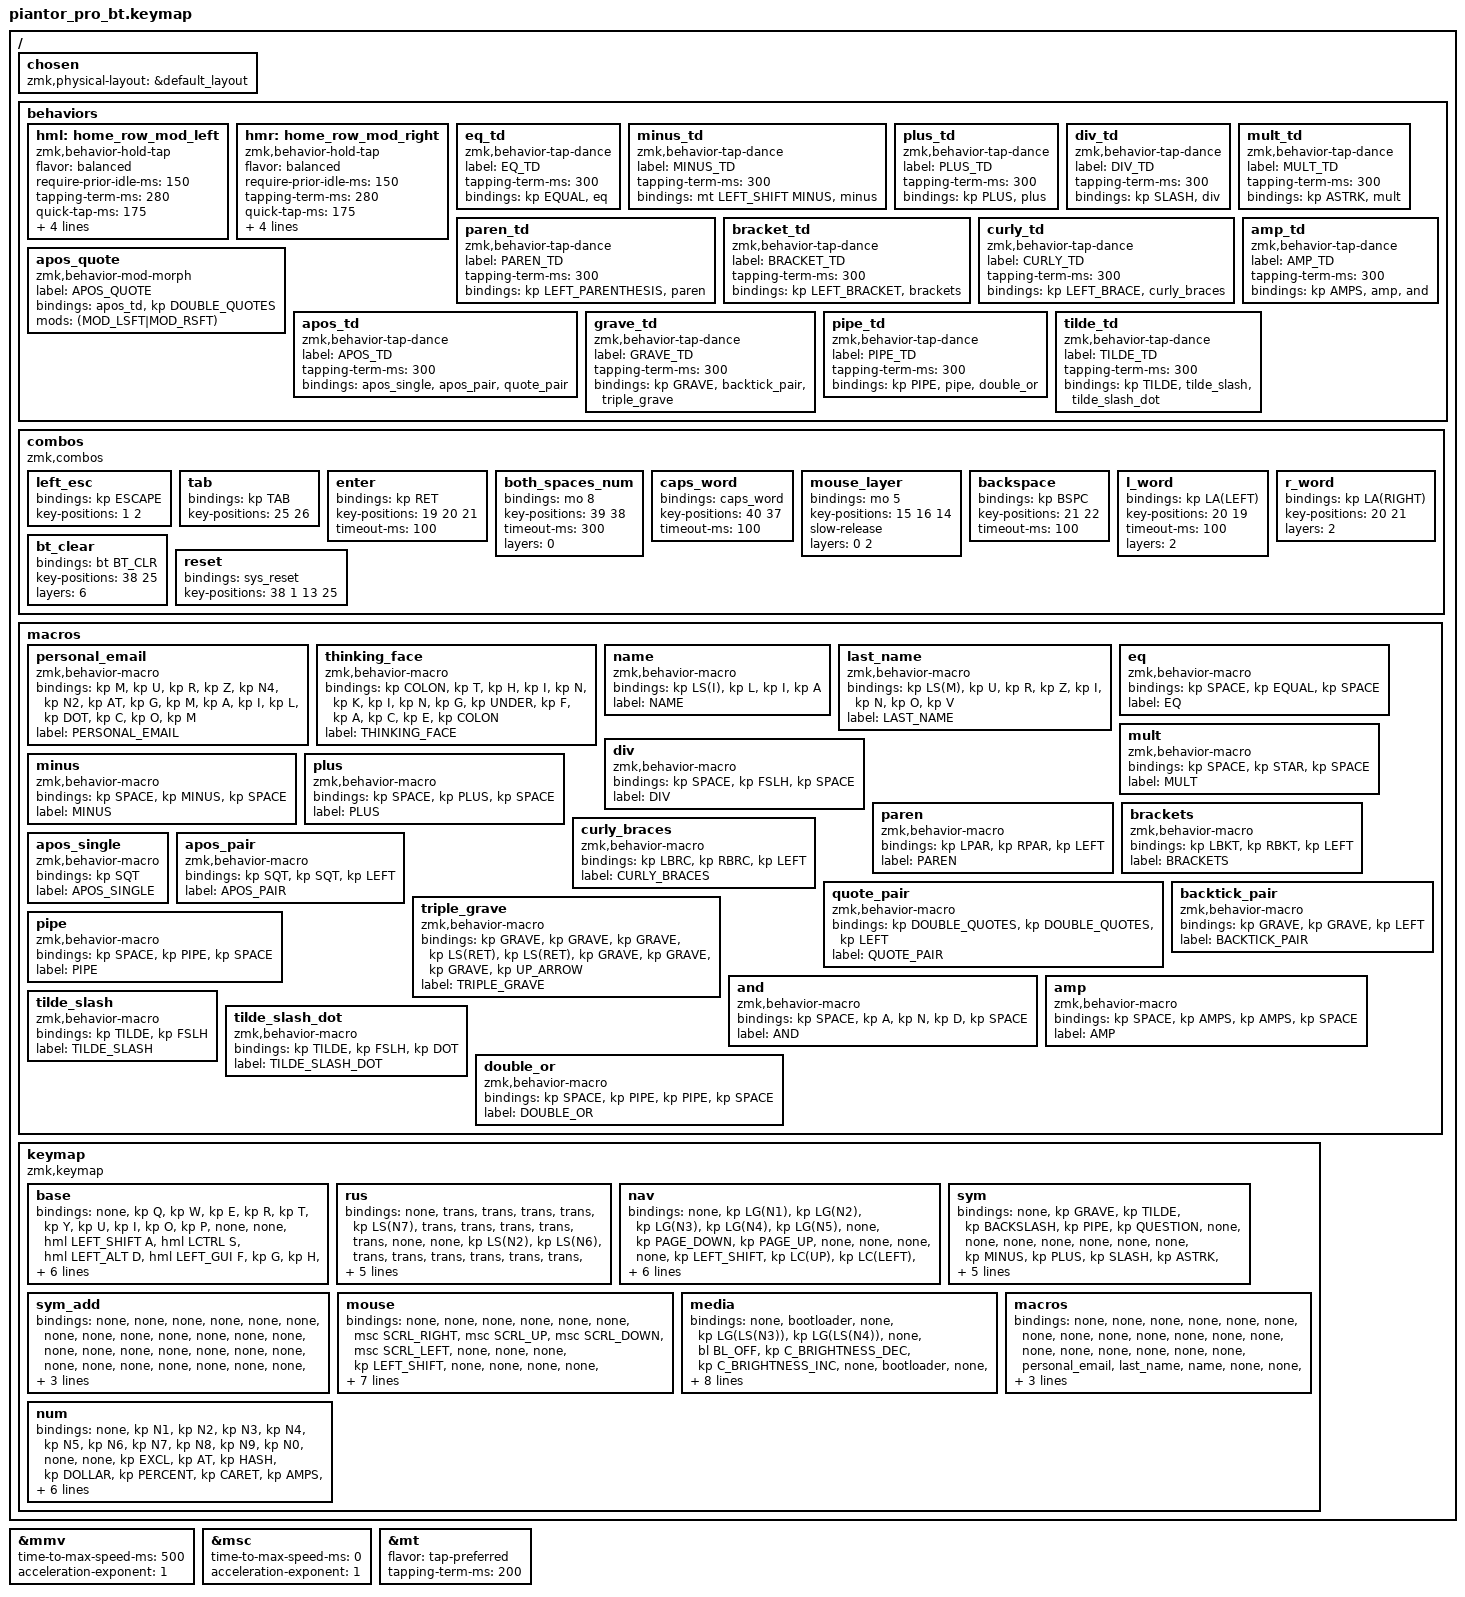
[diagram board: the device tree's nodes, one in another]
//
//                                                        ▀▀▀▀▀     ▀▀▀▀▀          ▀▀█▀▀
//                                                        ▄▀▀▀▄  ▄  ▄▀▀▀▄  ▄  ▄▀▀▀▄  █  ▄▀▀▀▄
//                                                        █   █  █  █   █  █  █   █  █  █   █
//                                                         ▀▀▀   █   ▀▀▀   █   ▀▀▀   ▀   ▀▀▀
//                                                               █      ▄▄▄█▄▄▄    █   █
//                                                              ▀      █  █  █     █▄█
//                                                             ▀▀▀▀▀    █  █  █      ▀
//                                                                      ▀  ▀  ▀
//
// ▄▄▄▄▄▄▄▄▄▄▄▄▄▄▄▄▄▄▄▄▄▄▄▄▄▄▄▄▄▄▄▄▄▄▄▄▄▄▄▄▄▄▄▄▄▄▄▄▄▄▄▄▄▄▄▄▄▄▄▄▄▄▄▄▄▄▄▄▄▄▄▄▄▄▄▄▄▄▄▄▄▄▄▄▄▄▄▄▄▄▄▄▄▄▄▄▄▄▄▄▄▄▄▄▄▄▄▄▄▄▄▄▄▄▄▄▄▄▄▄▄▄▄▄▄▄▄▄▄▄▄▄▄▄▄▄▄▄▄▄▄▄▄▄▄▄▄▄▄

#define ZMK_POINTING_DEFAULT_MOVE_VAL 1800
#define ZMK_POINTING_DEFAULT_SCRL_VAL 25

#include <behaviors.dtsi>
#include <dt-bindings/zmk/backlight.h>
#include <dt-bindings/zmk/bt.h>
#include <dt-bindings/zmk/keys.h>
#include <dt-bindings/zmk/pointing.h>

&mmv {
    time-to-max-speed-ms = <500>;
    acceleration-exponent = <1>;
};

&msc {
    time-to-max-speed-ms = <0>;
    acceleration-exponent = <1>;
};

&mt {
    flavor = "tap-preferred";
    tapping-term-ms = <200>;
};

/ {
    chosen { zmk,physical-layout = &default_layout; };
};

/ {
    behaviors {
        hml: home_row_mod_left {
            compatible = "zmk,behavior-hold-tap";
            #binding-cells = <2>;
            flavor = "balanced";
            require-prior-idle-ms = <150>;
            tapping-term-ms = <280>;
            quick-tap-ms = <175>;
            bindings = <&kp>, <&kp>;

            hold-trigger-key-positions = <6 18 30 19 7 8 20 32 31 9 21 33 10 22 34>;
            hold-trigger-on-release;
        };

        hmr: home_row_mod_right {
            compatible = "zmk,behavior-hold-tap";
            #binding-cells = <2>;
            flavor = "balanced";
            require-prior-idle-ms = <150>;
            tapping-term-ms = <280>;
            quick-tap-ms = <175>;
            bindings = <&kp>, <&kp>;

            hold-trigger-key-positions = <1 1 2 5 13 14 15 16 17 25 26 27 28 29 3 4>;
            hold-trigger-on-release;
        };

        eq_td: eq_td {
            compatible = "zmk,behavior-tap-dance";
            label = "EQ_TD";
            #binding-cells = <0>;
            tapping-term-ms = <300>;
            bindings = <&kp EQUAL>, <&eq>;
        };

        minus_td: minus_td {
            compatible = "zmk,behavior-tap-dance";
            label = "MINUS_TD";
            #binding-cells = <0>;
            tapping-term-ms = <300>;
            bindings = <&mt LEFT_SHIFT MINUS>, <&minus>;
        };

        plus_td: plus_td {
            compatible = "zmk,behavior-tap-dance";
            label = "PLUS_TD";
            #binding-cells = <0>;
            tapping-term-ms = <300>;
            bindings = <&kp PLUS>, <&plus>;
        };

        div_td: div_td {
            compatible = "zmk,behavior-tap-dance";
            label = "DIV_TD";
            #binding-cells = <0>;
            tapping-term-ms = <300>;
            bindings = <&kp SLASH>, <&div>;
        };

        mult_td: mult_td {
            compatible = "zmk,behavior-tap-dance";
            label = "MULT_TD";
            #binding-cells = <0>;
            tapping-term-ms = <300>;
            bindings = <&kp ASTRK>, <&mult>;
        };

        paren_td: paren_td {
            compatible = "zmk,behavior-tap-dance";
            label = "PAREN_TD";
            #binding-cells = <0>;
            tapping-term-ms = <300>;
            bindings = <&kp LEFT_PARENTHESIS>, <&paren>;
        };

        bracket_td: bracket_td {
            compatible = "zmk,behavior-tap-dance";
            label = "BRACKET_TD";
            #binding-cells = <0>;
            tapping-term-ms = <300>;
            bindings = <&kp LEFT_BRACKET>, <&brackets>;
        };

        curly_td: curly_td {
            compatible = "zmk,behavior-tap-dance";
            label = "CURLY_TD";
            #binding-cells = <0>;
            tapping-term-ms = <300>;
            bindings = <&kp LEFT_BRACE>, <&curly_braces>;
        };

        apos_quote: apos_quote {
            compatible = "zmk,behavior-mod-morph";
            label = "APOS_QUOTE";
            bindings = <&apos_td>, <&kp DOUBLE_QUOTES>;

            #binding-cells = <0>;
            mods = <(MOD_LSFT|MOD_RSFT)>;
        };

        apos_td: apos_td {
            compatible = "zmk,behavior-tap-dance";
            label = "APOS_TD";
            #binding-cells = <0>;
            tapping-term-ms = <300>;
            bindings = <&apos_single>, <&apos_pair>, <&quote_pair>;
        };

        grave_td: grave_td {
            compatible = "zmk,behavior-tap-dance";
            label = "GRAVE_TD";
            #binding-cells = <0>;
            tapping-term-ms = <300>;
            bindings = <&kp GRAVE>, <&backtick_pair>, <&triple_grave>;
        };

        pipe_td: pipe_td {
            compatible = "zmk,behavior-tap-dance";
            label = "PIPE_TD";
            #binding-cells = <0>;
            tapping-term-ms = <300>;
            bindings = <&kp PIPE>, <&pipe>, <&double_or>;
        };

        amp_td: amp_td {
            compatible = "zmk,behavior-tap-dance";
            label = "AMP_TD";
            #binding-cells = <0>;
            tapping-term-ms = <300>;
            bindings = <&kp AMPS>, <&amp>, <&and>;
        };

        tilde_td: tilde_td {
            compatible = "zmk,behavior-tap-dance";
            label = "TILDE_TD";
            #binding-cells = <0>;
            tapping-term-ms = <300>;
            bindings = <&kp TILDE>, <&tilde_slash>, <&tilde_slash_dot>;
        };
    };
};

/ {
    combos {
        compatible = "zmk,combos";

        left_esc {
            bindings = <&kp ESCAPE>;
            key-positions = <1 2>;
        };

        tab {
            bindings = <&kp TAB>;
            key-positions = <25 26>;
        };

        enter {
            bindings = <&kp RET>;
            key-positions = <19 20 21>;
            timeout-ms = <100>;
        };

        // Both Spaces → num (matches Vial combo LT4+LT3 → MO(8))
        both_spaces_num {
            bindings = <&mo 8>;
            key-positions = <39 38>;
            timeout-ms = <300>;
            layers = <0>;
        };

        caps_word {
            bindings = <&caps_word>;
            key-positions = <40 37>;
            timeout-ms = <100>;
        };

        mouse_layer {
            bindings = <&mo 5>;
            key-positions = <15 16 14>;
            slow-release;
            layers = <0 2>;
        };

        backspace {
            bindings = <&kp BSPC>;
            key-positions = <21 22>;
            timeout-ms = <100>;
        };

        l_word {
            bindings = <&kp LA(LEFT)>;
            key-positions = <20 19>;
            timeout-ms = <100>;
            layers = <2>;
        };

        r_word {
            bindings = <&kp LA(RIGHT)>;
            key-positions = <20 21>;
            layers = <2>;
        };

        bt_clear {
            bindings = <&bt BT_CLR>;
            key-positions = <38 25>;
            layers = <6>;
        };

        reset {
            bindings = <&sys_reset>;
            key-positions = <38 1 13 25>;
        };
    };

    macros {
        personal_email: personal_email {
            compatible = "zmk,behavior-macro";
            #binding-cells = <0>;
            bindings = <&kp M &kp U &kp R &kp Z &kp N4 &kp N2 &kp AT &kp G &kp M &kp A &kp I &kp L &kp DOT &kp C &kp O &kp M>;
            label = "PERSONAL_EMAIL";
        };

        thinking_face: thinking_face {
            compatible = "zmk,behavior-macro";
            #binding-cells = <0>;
            bindings = <&kp COLON &kp T &kp H &kp I &kp N &kp K &kp I &kp N &kp G &kp UNDER &kp F &kp A &kp C &kp E &kp COLON>;
            label = "THINKING_FACE";
        };

        name: name {
            compatible = "zmk,behavior-macro";
            #binding-cells = <0>;
            bindings = <&kp LS(I) &kp L &kp I &kp A>;
            label = "NAME";
        };

        last_name: last_name {
            compatible = "zmk,behavior-macro";
            #binding-cells = <0>;
            bindings = <&kp LS(M) &kp U &kp R &kp Z &kp I &kp N &kp O &kp V>;
            label = "LAST_NAME";
        };

        eq: eq {
            compatible = "zmk,behavior-macro";
            #binding-cells = <0>;
            bindings = <&kp SPACE &kp EQUAL &kp SPACE>;
            label = "EQ";
        };

        mult: mult {
            compatible = "zmk,behavior-macro";
            #binding-cells = <0>;
            bindings = <&kp SPACE &kp STAR &kp SPACE>;
            label = "MULT";
        };

        div: div {
            compatible = "zmk,behavior-macro";
            #binding-cells = <0>;
            bindings = <&kp SPACE &kp FSLH &kp SPACE>;
            label = "DIV";
        };

        minus: minus {
            compatible = "zmk,behavior-macro";
            #binding-cells = <0>;
            bindings = <&kp SPACE &kp MINUS &kp SPACE>;
            label = "MINUS";
        };

        plus: plus {
            compatible = "zmk,behavior-macro";
            #binding-cells = <0>;
            bindings = <&kp SPACE &kp PLUS &kp SPACE>;
            label = "PLUS";
        };

        paren: paren {
            compatible = "zmk,behavior-macro";
            #binding-cells = <0>;
            bindings = <&kp LPAR &kp RPAR &kp LEFT>;
            label = "PAREN";
        };

        brackets: brackets {
            compatible = "zmk,behavior-macro";
            #binding-cells = <0>;
            bindings = <&kp LBKT &kp RBKT &kp LEFT>;
            label = "BRACKETS";
        };

        curly_braces: curly_braces {
            compatible = "zmk,behavior-macro";
            #binding-cells = <0>;
            bindings = <&kp LBRC &kp RBRC &kp LEFT>;
            label = "CURLY_BRACES";
        };

        apos_single: apos_single {
            compatible = "zmk,behavior-macro";
            #binding-cells = <0>;
            bindings = <&kp SQT>;
            label = "APOS_SINGLE";
        };

        apos_pair: apos_pair {
            compatible = "zmk,behavior-macro";
            #binding-cells = <0>;
            bindings = <&kp SQT &kp SQT &kp LEFT>;
            label = "APOS_PAIR";
        };

        quote_pair: quote_pair {
            compatible = "zmk,behavior-macro";
            #binding-cells = <0>;
            bindings = <&kp DOUBLE_QUOTES &kp DOUBLE_QUOTES &kp LEFT>;
            label = "QUOTE_PAIR";
        };

        backtick_pair: backtick_pair {
            compatible = "zmk,behavior-macro";
            #binding-cells = <0>;
            bindings = <&kp GRAVE &kp GRAVE &kp LEFT>;
            label = "BACKTICK_PAIR";
        };

        triple_grave: triple_grave {
            compatible = "zmk,behavior-macro";
            #binding-cells = <0>;
            bindings = <&kp GRAVE &kp GRAVE &kp GRAVE &kp LS(RET) &kp LS(RET) &kp GRAVE &kp GRAVE &kp GRAVE &kp UP_ARROW>;
            label = "TRIPLE_GRAVE";
        };

        pipe: pipe {
            compatible = "zmk,behavior-macro";
            #binding-cells = <0>;
            bindings = <&kp SPACE &kp PIPE &kp SPACE>;
            label = "PIPE";
        };

        and: and {
            compatible = "zmk,behavior-macro";
            #binding-cells = <0>;
            bindings = <&kp SPACE &kp A &kp N &kp D &kp SPACE>;
            label = "AND";
        };

        amp: amp {
            compatible = "zmk,behavior-macro";
            #binding-cells = <0>;
            bindings = <&kp SPACE &kp AMPS &kp AMPS &kp SPACE>;
            label = "AMP";
        };

        tilde_slash: tilde_slash {
            compatible = "zmk,behavior-macro";
            #binding-cells = <0>;
            bindings = <&kp TILDE &kp FSLH>;
            label = "TILDE_SLASH";
        };

        tilde_slash_dot: tilde_slash_dot {
            compatible = "zmk,behavior-macro";
            #binding-cells = <0>;
            bindings = <&kp TILDE &kp FSLH &kp DOT>;
            label = "TILDE_SLASH_DOT";
        };

        double_or: double_or {
            compatible = "zmk,behavior-macro";
            #binding-cells = <0>;
            bindings = <&kp SPACE &kp PIPE &kp PIPE &kp SPACE>;
            label = "DOUBLE_OR";
        };
    };

    keymap {
        compatible = "zmk,keymap";

        base {
            bindings = <
&none  &kp Q  &kp W  &kp E  &kp R  &kp T  &kp Y  &kp U  &kp I  &kp O  &kp P  &none  &none  &hml LEFT_SHIFT A  &hml LCTRL S  &hml LEFT_ALT D  &hml LEFT_GUI F  &kp G  &kp H  &hmr LEFT_GUI J  &hmr RIGHT_ALT K  &hmr RCTRL L  &hmr RIGHT_SHIFT SEMI  &none  &none  &kp Z  &kp X  &kp C  &kp V  &kp B  &kp N  &kp M  &kp COMMA  &kp DOT  &apos_quote  &none  &mo 7  &mo 2  &lt 4 SPACE  &lt 3 SPACE  &mo 1  &mo 6
            >;
        };

        rus {
            bindings = <
&none  &trans  &trans  &trans  &trans  &kp LS(N7)  &trans  &trans  &trans  &trans  &trans  &none  &none  &kp LS(N2)  &kp LS(N6)  &trans  &trans  &trans  &trans  &trans  &trans  &trans  &trans  &none  &none  &kp RIGHT_BRACKET  &kp LEFT_BRACKET  &kp LS(SLASH)  &kp SLASH  &trans  &trans  &trans  &trans  &trans  &trans  &none  &trans  &trans  &trans  &trans  &trans  &trans
            >;
        };

        nav {
            bindings = <
&none  &kp LG(N1)  &kp LG(N2)  &kp LG(N3)  &kp LG(N4)  &kp LG(N5)  &none  &kp PAGE_DOWN  &kp PAGE_UP  &none  &none  &none  &none  &kp LEFT_SHIFT  &kp LC(UP)  &kp LC(LEFT)  &kp LC(RIGHT)  &none  &kp LEFT  &kp DOWN  &kp UP  &kp RIGHT  &kp BSPC  &none  &none  &none  &none  &kp LG(LS(LEFT_BRACKET))  &kp LG(LS(RIGHT_BRACKET))  &none  &none  &none  &none  &none  &none  &none  &none  &none  &none  &kp LG(SPACE)  &none  &none
            >;
        };

        // Right Space — operators + []; opposite (left) Space → num
        sym {
            bindings = <
&none  &kp GRAVE  &kp TILDE  &kp BACKSLASH  &kp PIPE  &kp QUESTION  &none  &none  &none  &none  &none  &none  &none  &kp MINUS  &kp PLUS  &kp SLASH  &kp ASTRK  &kp EQUAL  &none  &kp LEFT_BRACKET  &kp RIGHT_BRACKET  &none  &none  &none  &none  &kp UNDER  &none  &none  &none  &none  &none  &none  &none  &none  &none  &none  &none  &none  &mo 8  &none  &none  &none
            >;
        };

        // Left Space — / only (right bottom pinky); opposite (right) Space → num
        sym_add {
            bindings = <
&none  &none  &none  &none  &none  &none  &none  &none  &none  &none  &none  &none  &none  &none  &none  &none  &none  &none  &none  &none  &none  &none  &none  &none  &none  &none  &none  &none  &none  &none  &none  &none  &none  &none  &kp SLASH  &none  &none  &none  &none  &mo 8  &none  &none
            >;
        };

        mouse {
            bindings = <
&none  &none  &none  &none  &none  &none  &msc SCRL_RIGHT  &msc SCRL_UP  &msc SCRL_DOWN  &msc SCRL_LEFT  &none  &none  &none  &kp LEFT_SHIFT  &none  &none  &none  &none  &mmv MOVE_LEFT  &mmv MOVE_DOWN  &mmv MOVE_UP  &mmv MOVE_RIGHT  &none  &none  &none  &none  &none  &none  &none  &none  &none  &kp LG(LS(LEFT_BRACKET))  &kp LG(LS(RIGHT_BRACKET))  &none  &none  &none  &trans  &trans  &kp LEFT_GUI  &mkp MB1  &mkp MB2  &none
            >;
        };

        // ZMK-only: keep &bootloader and &bt BT_SEL* (and &bl BL_OFF) — not in Vial.
        media {
            bindings = <
&none  &bootloader  &none  &kp LG(LS(N3))  &kp LG(LS(N4))  &none  &bl BL_OFF  &kp C_BRIGHTNESS_DEC  &kp C_BRIGHTNESS_INC  &none  &bootloader  &none  &none  &kp LG(LA(LC(LEFT)))  &kp LG(LA(LC(F)))  &kp LG(LC(F))  &kp LG(LA(LC(RIGHT)))  &none  &kp C_PLAY_PAUSE  &kp C_VOL_DN  &kp C_VOLUME_UP  &kp K_MUTE  &none  &none  &none  &bt BT_SEL 0  &bt BT_SEL 1  &bt BT_SEL 2  &bt BT_SEL 3  &bt BT_SEL 4  &none  &none  &none  &none  &none  &none  &none  &none  &none  &none  &none  &none
            >;
        };

        macros {
            bindings = <
&none  &none  &none  &none  &none  &none  &none  &none  &none  &none  &none  &none  &none  &none  &none  &none  &none  &none  &none  &personal_email  &last_name  &name  &none  &none  &none  &none  &none  &none  &none  &none  &none  &none  &none  &none  &none  &none  &none  &none  &none  &none  &none  &none
            >;
        };

        // Opposite Space from sym/sym_add — QWERTY nums + symbols + brackets (no HRM)
        num {
            bindings = <
&none  &kp N1  &kp N2  &kp N3  &kp N4  &kp N5  &kp N6  &kp N7  &kp N8  &kp N9  &kp N0  &none  &none  &kp EXCL  &kp AT  &kp HASH  &kp DOLLAR  &kp PERCENT  &kp CARET  &kp AMPS  &kp ASTRK  &kp LPAR  &kp RPAR  &none  &none  &kp LESS_THAN  &kp LEFT_BRACKET  &kp LEFT_BRACE  &none  &none  &none  &none  &kp RIGHT_BRACE  &kp RIGHT_BRACKET  &kp GREATER_THAN  &none  &none  &none  &none  &none  &none  &none
            >;
        };
    };
};
